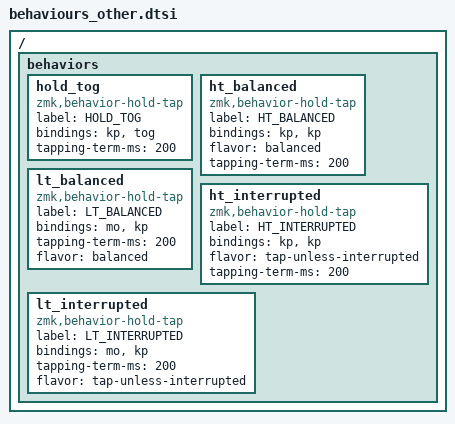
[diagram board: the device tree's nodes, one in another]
#include <dt-bindings/zmk/outputs.h>

#define TD_TAPPING_TERM 300

/ {
    behaviors {
        hold_tog: hold_tog {
            compatible = "zmk,behavior-hold-tap";
            label = "HOLD_TOG";
            bindings = <&kp>, <&tog>;

            #binding-cells = <2>;
            tapping-term-ms = <200>;
        };

        ht_balanced: ht_balanced {
            compatible = "zmk,behavior-hold-tap";
            label = "HT_BALANCED";
            bindings = <&kp>, <&kp>;

            #binding-cells = <2>;
            flavor = "balanced";
            tapping-term-ms = <200>;
        };

        lt_balanced: lt_balanced {
            compatible = "zmk,behavior-hold-tap";
            label = "LT_BALANCED";
            bindings = <&mo>, <&kp>;

            #binding-cells = <2>;
            tapping-term-ms = <200>;
            flavor = "balanced";
        };

        ht_interrupted: ht_interrupted {
            compatible = "zmk,behavior-hold-tap";
            label = "HT_INTERRUPTED";
            bindings = <&kp>, <&kp>;

            #binding-cells = <2>;
            flavor = "tap-unless-interrupted";
            tapping-term-ms = <200>;
        };

        lt_interrupted: lt_interrupted {
            compatible = "zmk,behavior-hold-tap";
            label = "LT_INTERRUPTED";
            bindings = <&mo>, <&kp>;

            #binding-cells = <2>;
            tapping-term-ms = <200>;
            flavor = "tap-unless-interrupted";
        };
    };
};
